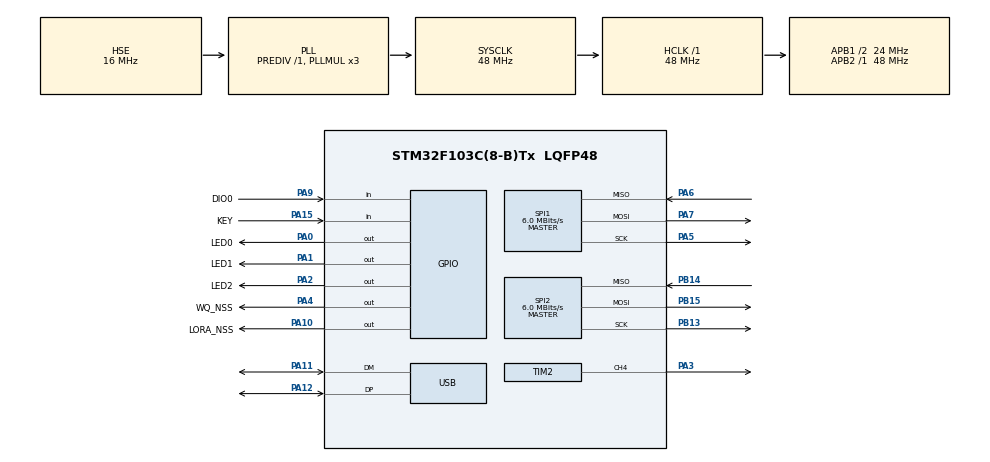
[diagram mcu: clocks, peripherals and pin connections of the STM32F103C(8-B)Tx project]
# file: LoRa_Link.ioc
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Mcu.Family=STM32F1
Mcu.Name=STM32F103C(8-B)Tx
Mcu.Package=LQFP48
NVIC.PriorityGroup=NVIC_PRIORITYGROUP_4
NVIC.TIM4_IRQn=true\:0\:0\:false\:false\:true\:true\:true\:true
NVIC.USB_HP_CAN1_TX_IRQn=true\:0\:0\:false\:false\:true\:true\:true\:true
NVIC.USB_LP_CAN1_RX0_IRQn=true\:0\:0\:false\:false\:true\:false\:true\:true
PA0-WKUP.GPIO_Label=LED0
PA0-WKUP.Signal=GPIO_Output
PA1.GPIO_Label=LED1
PA1.Signal=GPIO_Output
PA10.GPIO_Label=LORA_NSS
PA10.Signal=GPIO_Output
PA11.Mode=Device
PA11.Signal=USB_DM
PA12.Mode=Device
PA12.Signal=USB_DP
PA13.Mode=Serial_Wire
PA13.Signal=SYS_JTMS-SWDIO
PA14.Mode=Serial_Wire
PA14.Signal=SYS_JTCK-SWCLK
PA15.GPIO_Label=KEY
PA15.GPIO_PuPd=GPIO_PULLUP
PA15.Signal=GPIO_Input
PA2.GPIO_Label=LED2
PA2.Signal=GPIO_Output
PA3.Signal=S_TIM2_CH4
PA4.GPIO_Label=WQ_NSS
PA4.Signal=GPIO_Output
PA5.Mode=Full_Duplex_Master
PA5.Signal=SPI1_SCK
PA6.Mode=Full_Duplex_Master
PA6.Signal=SPI1_MISO
PA7.Mode=Full_Duplex_Master
PA7.Signal=SPI1_MOSI
PA9.GPIO_Label=DIO0
PA9.Signal=GPIO_Input
PB13.Mode=Full_Duplex_Master
PB13.Signal=SPI2_SCK
PB14.Mode=Full_Duplex_Master
PB14.Signal=SPI2_MISO
PB15.Mode=Full_Duplex_Master
PB15.Signal=SPI2_MOSI
PD0-OSC_IN.Mode=HSE-External-Oscillator
PD0-OSC_IN.Signal=RCC_OSC_IN
PD1-OSC_OUT.Mode=HSE-External-Oscillator
PD1-OSC_OUT.Signal=RCC_OSC_OUT
ProjectManager.HeapSize=0x200
ProjectManager.StackSize=0x400
ProjectManager.TargetToolchain=STM32CubeIDE
RCC.AHBFreq_Value=48000000
RCC.APB1CLKDivider=RCC_HCLK_DIV2
RCC.APB1Freq_Value=24000000
RCC.APB1TimFreq_Value=48000000
RCC.APB2Freq_Value=48000000
RCC.APB2TimFreq_Value=48000000
RCC.DATA_CACHE_ENABLE=1
RCC.EnbaleCSS=true
RCC.HCLKFreq_Value=48000000
RCC.HSE_VALUE=16000000
RCC.INSTRUCTION_CACHE_ENABLE=1
RCC.LSE_Drive_CapabilityArg=+LSE_Drive_Capability
RCC.MSIAutoCalibration=DISABLED
RCC.MSICalibrationValue=0
RCC.PLLMUL=RCC_PLL_MUL3
RCC.PWR_Regulator_Voltage_Scale=PWR_REGULATOR_VOLTAGE_SCALE1
RCC.SYSCLKFreq_VALUE=48000000
RCC.SYSCLKSource=RCC_SYSCLKSOURCE_PLLCLK
RCC.USBFreq_Value=48000000
SH.S_TIM2_CH4.0=TIM2_CH4,PWM Generation4 CH4
SPI1.BaudRatePrescaler=SPI_BAUDRATEPRESCALER_8
SPI1.CalculateBaudRate=6.0 MBits/s
SPI1.Direction=SPI_DIRECTION_2LINES
SPI1.Mode=SPI_MODE_MASTER
SPI1.VirtualType=VM_MASTER
SPI2.BaudRatePrescaler=SPI_BAUDRATEPRESCALER_4
SPI2.CalculateBaudRate=6.0 MBits/s
SPI2.Direction=SPI_DIRECTION_2LINES
SPI2.Mode=SPI_MODE_MASTER
SPI2.VirtualType=VM_MASTER
TIM2.Channel-PWM\ Generation4\ CH4=TIM_CHANNEL_4
TIM2.Period=10
TIM2.Prescaler=0
TIM4.Period=1000
TIM4.Prescaler=10000
USB_DEVICE.APP_RX_DATA_SIZE=64
USB_DEVICE.APP_TX_DATA_SIZE=64
USB_DEVICE.CLASS_NAME_FS=CDC
USB_DEVICE.VirtualMode=Cdc
USB_DEVICE.VirtualModeFS=Cdc_FS
VP_TIM2_VS_ClockSourceINT.Mode=Internal
VP_TIM4_VS_ClockSourceINT.Mode=Internal
VP_USB_DEVICE_VS_USB_DEVICE_CDC_FS.Mode=CDC_FS
board=custom

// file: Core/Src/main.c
/* USER CODE BEGIN Header */
/**
  ******************************************************************************
  * @file           : main.c
  * @brief          : Main program body
  ******************************************************************************
  * @attention
  *
  * Copyright (c) 2024 STMicroelectronics.
  * All rights reserved.
  *
  * This software is licensed under terms that can be found in the LICENSE file
  * in the root directory of this software component.
  * If no LICENSE file comes with this software, it is provided AS-IS.
  *
  ******************************************************************************
  */
/* USER CODE END Header */
#include "main.h"
#include "usb_device.h"

/* USER CODE BEGIN Includes */
#include "user.h"
/* USER CODE END Includes */

SPI_HandleTypeDef hspi1;
SPI_HandleTypeDef hspi2;

TIM_HandleTypeDef htim2;
TIM_HandleTypeDef htim4;

void SystemClock_Config(void);
static void MX_GPIO_Init(void);
static void MX_SPI1_Init(void);
static void MX_SPI2_Init(void);
static void MX_TIM2_Init(void);
static void MX_TIM4_Init(void);

int main(void)
{

  /* MCU Configuration--------------------------------------------------------*/

  /* Reset of all peripherals, Initializes the Flash interface and the Systick. */
  HAL_Init();

  /* Configure the system clock */
  SystemClock_Config();

  /* Initialize all configured peripherals */
  MX_GPIO_Init();
  MX_SPI1_Init();
  MX_SPI2_Init();
  MX_TIM2_Init();
  MX_TIM4_Init();
  MX_USB_DEVICE_Init();
  /* USER CODE BEGIN 2 */
  USER_Init();

  /* USER CODE END 2 */

  /* Infinite loop */
  /* USER CODE BEGIN WHILE */
  while (1)
  {
	  USER_Loop();
    /* USER CODE END WHILE */

  }
}

void SystemClock_Config(void)
{
  RCC_OscInitTypeDef RCC_OscInitStruct = {0};
  RCC_ClkInitTypeDef RCC_ClkInitStruct = {0};
  RCC_PeriphCLKInitTypeDef PeriphClkInit = {0};

  /** Initializes the RCC Oscillators according to the specified parameters
  * in the RCC_OscInitTypeDef structure.
  */
  RCC_OscInitStruct.OscillatorType = RCC_OSCILLATORTYPE_HSE;
  RCC_OscInitStruct.HSEState = RCC_HSE_ON;
  RCC_OscInitStruct.HSEPredivValue = RCC_HSE_PREDIV_DIV1;
  RCC_OscInitStruct.HSIState = RCC_HSI_ON;
  RCC_OscInitStruct.PLL.PLLState = RCC_PLL_ON;
  RCC_OscInitStruct.PLL.PLLSource = RCC_PLLSOURCE_HSE;
  RCC_OscInitStruct.PLL.PLLMUL = RCC_PLL_MUL3;
  if (HAL_RCC_OscConfig(&RCC_OscInitStruct) != HAL_OK)
  {
    Error_Handler();
  }

  /** Initializes the CPU, AHB and APB buses clocks
  */
  RCC_ClkInitStruct.ClockType = RCC_CLOCKTYPE_HCLK|RCC_CLOCKTYPE_SYSCLK
                              |RCC_CLOCKTYPE_PCLK1|RCC_CLOCKTYPE_PCLK2;
  RCC_ClkInitStruct.SYSCLKSource = RCC_SYSCLKSOURCE_PLLCLK;
  RCC_ClkInitStruct.AHBCLKDivider = RCC_SYSCLK_DIV1;
  RCC_ClkInitStruct.APB1CLKDivider = RCC_HCLK_DIV2;
  RCC_ClkInitStruct.APB2CLKDivider = RCC_HCLK_DIV1;

  if (HAL_RCC_ClockConfig(&RCC_ClkInitStruct, FLASH_LATENCY_1) != HAL_OK)
  {
    Error_Handler();
  }
  PeriphClkInit.PeriphClockSelection = RCC_PERIPHCLK_USB;
  PeriphClkInit.UsbClockSelection = RCC_USBCLKSOURCE_PLL;
  if (HAL_RCCEx_PeriphCLKConfig(&PeriphClkInit) != HAL_OK)
  {
    Error_Handler();
  }

  /** Enables the Clock Security System
  */
  HAL_RCC_EnableCSS();
}

static void MX_SPI1_Init(void)
{

  /* SPI1 parameter configuration*/
  hspi1.Instance = SPI1;
  hspi1.Init.Mode = SPI_MODE_MASTER;
  hspi1.Init.Direction = SPI_DIRECTION_2LINES;
  hspi1.Init.DataSize = SPI_DATASIZE_8BIT;
  hspi1.Init.CLKPolarity = SPI_POLARITY_LOW;
  hspi1.Init.CLKPhase = SPI_PHASE_1EDGE;
  hspi1.Init.NSS = SPI_NSS_SOFT;
  hspi1.Init.BaudRatePrescaler = SPI_BAUDRATEPRESCALER_8;
  hspi1.Init.FirstBit = SPI_FIRSTBIT_MSB;
  hspi1.Init.TIMode = SPI_TIMODE_DISABLE;
  hspi1.Init.CRCCalculation = SPI_CRCCALCULATION_DISABLE;
  hspi1.Init.CRCPolynomial = 10;
  if (HAL_SPI_Init(&hspi1) != HAL_OK)
  {
    Error_Handler();
  }

}

static void MX_SPI2_Init(void)
{

  /* SPI2 parameter configuration*/
  hspi2.Instance = SPI2;
  hspi2.Init.Mode = SPI_MODE_MASTER;
  hspi2.Init.Direction = SPI_DIRECTION_2LINES;
  hspi2.Init.DataSize = SPI_DATASIZE_8BIT;
  hspi2.Init.CLKPolarity = SPI_POLARITY_LOW;
  hspi2.Init.CLKPhase = SPI_PHASE_1EDGE;
  hspi2.Init.NSS = SPI_NSS_SOFT;
  hspi2.Init.BaudRatePrescaler = SPI_BAUDRATEPRESCALER_4;
  hspi2.Init.FirstBit = SPI_FIRSTBIT_MSB;
  hspi2.Init.TIMode = SPI_TIMODE_DISABLE;
  hspi2.Init.CRCCalculation = SPI_CRCCALCULATION_DISABLE;
  hspi2.Init.CRCPolynomial = 10;
  if (HAL_SPI_Init(&hspi2) != HAL_OK)
  {
    Error_Handler();
  }

}

static void MX_TIM2_Init(void)
{

  TIM_ClockConfigTypeDef sClockSourceConfig = {0};
  TIM_MasterConfigTypeDef sMasterConfig = {0};
  TIM_OC_InitTypeDef sConfigOC = {0};

  htim2.Instance = TIM2;
  htim2.Init.Prescaler = 0;
  htim2.Init.CounterMode = TIM_COUNTERMODE_UP;
  htim2.Init.Period = 10;
  htim2.Init.ClockDivision = TIM_CLOCKDIVISION_DIV1;
  htim2.Init.AutoReloadPreload = TIM_AUTORELOAD_PRELOAD_DISABLE;
  if (HAL_TIM_Base_Init(&htim2) != HAL_OK)
  {
    Error_Handler();
  }
  sClockSourceConfig.ClockSource = TIM_CLOCKSOURCE_INTERNAL;
  if (HAL_TIM_ConfigClockSource(&htim2, &sClockSourceConfig) != HAL_OK)
  {
    Error_Handler();
  }
  if (HAL_TIM_PWM_Init(&htim2) != HAL_OK)
  {
    Error_Handler();
  }
  sMasterConfig.MasterOutputTrigger = TIM_TRGO_RESET;
  sMasterConfig.MasterSlaveMode = TIM_MASTERSLAVEMODE_DISABLE;
  if (HAL_TIMEx_MasterConfigSynchronization(&htim2, &sMasterConfig) != HAL_OK)
  {
    Error_Handler();
  }
  sConfigOC.OCMode = TIM_OCMODE_PWM1;
  sConfigOC.Pulse = 0;
  sConfigOC.OCPolarity = TIM_OCPOLARITY_HIGH;
  sConfigOC.OCFastMode = TIM_OCFAST_DISABLE;
  if (HAL_TIM_PWM_ConfigChannel(&htim2, &sConfigOC, TIM_CHANNEL_4) != HAL_OK)
  {
    Error_Handler();
  }
  HAL_TIM_MspPostInit(&htim2);

}

static void MX_TIM4_Init(void)
{

  TIM_ClockConfigTypeDef sClockSourceConfig = {0};
  TIM_MasterConfigTypeDef sMasterConfig = {0};

  htim4.Instance = TIM4;
  htim4.Init.Prescaler = 10000;
  htim4.Init.CounterMode = TIM_COUNTERMODE_UP;
  htim4.Init.Period = 1000;
  htim4.Init.ClockDivision = TIM_CLOCKDIVISION_DIV1;
  htim4.Init.AutoReloadPreload = TIM_AUTORELOAD_PRELOAD_DISABLE;
  if (HAL_TIM_Base_Init(&htim4) != HAL_OK)
  {
    Error_Handler();
  }
  sClockSourceConfig.ClockSource = TIM_CLOCKSOURCE_INTERNAL;
  if (HAL_TIM_ConfigClockSource(&htim4, &sClockSourceConfig) != HAL_OK)
  {
    Error_Handler();
  }
  sMasterConfig.MasterOutputTrigger = TIM_TRGO_RESET;
  sMasterConfig.MasterSlaveMode = TIM_MASTERSLAVEMODE_DISABLE;
  if (HAL_TIMEx_MasterConfigSynchronization(&htim4, &sMasterConfig) != HAL_OK)
  {
    Error_Handler();
  }

}

static void MX_GPIO_Init(void)
{
  GPIO_InitTypeDef GPIO_InitStruct = {0};

  /* GPIO Ports Clock Enable */
  __HAL_RCC_GPIOD_CLK_ENABLE();
  __HAL_RCC_GPIOA_CLK_ENABLE();
  __HAL_RCC_GPIOB_CLK_ENABLE();

  /*Configure GPIO pin Output Level */
  HAL_GPIO_WritePin(GPIOA, LED0_Pin|LED1_Pin|LED2_Pin|WQ_NSS_Pin
                          |LORA_NSS_Pin, GPIO_PIN_RESET);

  /*Configure GPIO pins : LED0_Pin LED1_Pin LED2_Pin WQ_NSS_Pin
                           LORA_NSS_Pin */
  GPIO_InitStruct.Pin = LED0_Pin|LED1_Pin|LED2_Pin|WQ_NSS_Pin
                          |LORA_NSS_Pin;
  GPIO_InitStruct.Mode = GPIO_MODE_OUTPUT_PP;
  GPIO_InitStruct.Pull = GPIO_NOPULL;
  GPIO_InitStruct.Speed = GPIO_SPEED_FREQ_LOW;
  HAL_GPIO_Init(GPIOA, &GPIO_InitStruct);

  /*Configure GPIO pin : DIO0_Pin */
  GPIO_InitStruct.Pin = DIO0_Pin;
  GPIO_InitStruct.Mode = GPIO_MODE_INPUT;
  GPIO_InitStruct.Pull = GPIO_NOPULL;
  HAL_GPIO_Init(DIO0_GPIO_Port, &GPIO_InitStruct);

  /*Configure GPIO pin : KEY_Pin */
  GPIO_InitStruct.Pin = KEY_Pin;
  GPIO_InitStruct.Mode = GPIO_MODE_INPUT;
  GPIO_InitStruct.Pull = GPIO_PULLUP;
  HAL_GPIO_Init(KEY_GPIO_Port, &GPIO_InitStruct);

}

void Error_Handler(void)
{
  __disable_irq();
  while (1)
  {
  }
}
